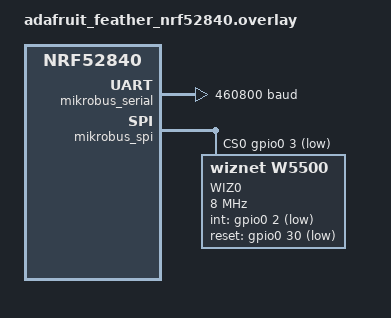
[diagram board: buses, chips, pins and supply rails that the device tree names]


// not needed but fixes upstream dts
&mikrobus_i2c {
	status = "disabled";
	clock-frequency = <I2C_BITRATE_STANDARD>;
};

&mikrobus_serial {
		current-speed = <460800>;
};


&mikrobus_spi {
	
	status = "okay";
	cs-gpios = <&gpio0 3 GPIO_ACTIVE_LOW>;	/* A5 */

	// enc424j600@0 {
	// 	status = "disabled";
	// 	compatible = "microchip,enc424j600";
	// 	reg = <0>;
	// 	spi-max-frequency = <20000000>;
	// 	int-gpios = <&mikrobus_header 7 GPIO_ACTIVE_LOW>;	/* PIO1_28 => PLU_IN3  */
	// 	label = "ETH_0";
	// };

	wizenet@0 {
		status = "okay";
		compatible = "wiznet,w5500";
		reg = <0>;
		spi-max-frequency = <8000000>;
		int-gpios = <&gpio0 2 GPIO_ACTIVE_LOW>;	/* PIO1_28 => PLU_IN3  */
		reset-gpios = <&gpio0 30 GPIO_ACTIVE_LOW>;	/* PIO1_28 => PLU_IN3  */
		label = "WIZ0";
	};
};

